# CH32V407 register map
Vendor: WCH Ltd.; File version: 1.0
Registers are 32-bit, read-write, reset 0x0 unless marked. A register's access mark holds for its fields unless they carry their own. Offsets are from the block's base; [hi:lo] are bit positions; {n}, {i} and the like mark numbered series.

## AFIO — Alternate function I/O
Base 0x40010000
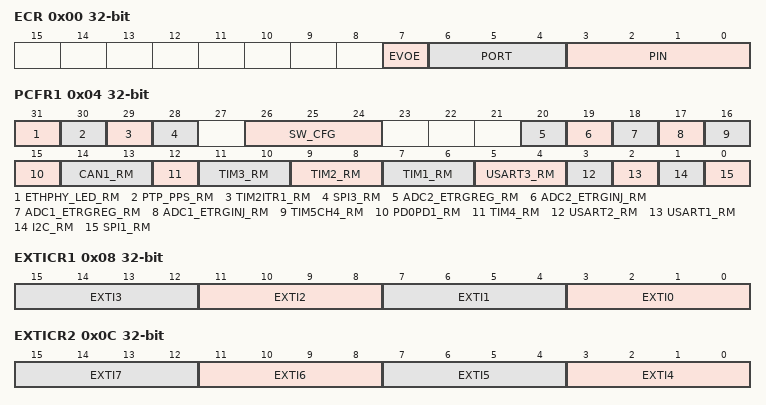
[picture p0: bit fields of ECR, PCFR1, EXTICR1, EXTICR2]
0x00 ECR — Event Control Register (AFIO_ECR)
  [7] EVOE — Event Output Enable
  [6:4] PORT — Port selection
  [3:0] PIN — Pin selection
0x04 PCFR1 — AF remap and debug I/O configuration register (AFIO_PCFR1)
  [31] ETHPHY_LED_RM — ETH PHY LED remapping
  [30] PTP_PPS_RM — Ethernet PTP_PPS remapping
  [29] TIM2ITR1_RM — TIM2 internally triggers 1 remapping
  [28] SPI3_RM — SPI3 remapping
  [26:24] SW_CFG — Serial wire JTAG configuration
  [20] ADC2_ETRGREG_RM — ADC 2 external trigger regular conversion remapping
  [19] ADC2_ETRGINJ_RM — ADC 2 External trigger injected conversion remapping
  [18] ADC1_ETRGREG_RM — ADC 1 external trigger regular conversion remapping
  [17] ADC1_ETRGINJ_RM — ADC 1 External trigger injected conversion remapping
  [16] TIM5CH4_RM — TIM5 channel4 internal remap
  [15] PD0PD1_RM — Port D0/Port D1 mapping on OSCIN/OSCOUT
  [14:13] CAN1_RM — CAN1 remapping
  [12] TIM4_RM — TIM4 remapping
  [11:10] TIM3_RM — TIM3 remapping
  [9:8] TIM2_RM — TIM2 remapping
  [7:6] TIM1_RM — TIM1 remapping
  [5:4] USART3_RM — USART3 remapping
  [3] USART2_RM — USART2 remapping
  [2] USART1_RM — USART1 remapping
  [1] I2C_RM — I2C remapping
  [0] SPI1_RM — SPI1 remapping
0x08 EXTICR1 — External interrupt configuration register 1 (AFIO_EXTICR1)
  [4n+3:4n] EXTI{n} (n=0..3) — EXTI{n} configuration
0x0C EXTICR2 — External interrupt configuration register 2 (AFIO_EXTICR2)
  [4n-13:4n-16] EXTI{n} (n=4..7) — EXTI{n} configuration
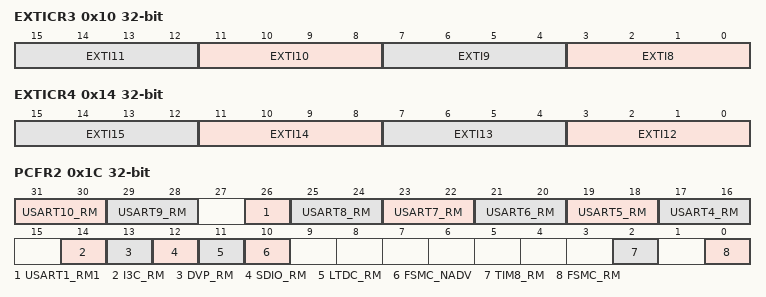
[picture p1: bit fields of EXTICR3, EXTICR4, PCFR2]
0x10 EXTICR3 — External interrupt configuration register 3 (AFIO_EXTICR3)
  [4n-29:4n-32] EXTI{n} (n=8..11) — EXTI{n} configuration
0x14 EXTICR4 — External interrupt configuration register 4 (AFIO_EXTICR4)
  [4n-45:4n-48] EXTI{n} (n=12..15) — EXTI{n} configuration
0x1C PCFR2 — AF remap and debug I/O configuration register (AFIO_PCFR2)
  [31:30] USART10_RM — USART10 remapping
  [29:28] USART9_RM — USART9 remapping
  [26] USART1_RM1 — UART1 remapping
  [2n+9:2n+8] USART{n}_RM (n=4..8) — USART{n} remapping
  [14] I3C_RM — I3C remapping
  [13] DVP_RM — DVP remapping
  [12] SDIO_RM — SDIO remapping
  [11] LTDC_RM — LTDC remapping
  [10] FSMC_NADV
  [2] TIM8_RM — TIM8 remapping
  [0] FSMC_RM — FSMC remapping

## DAC — Digital to analog converter
Base 0x40007400
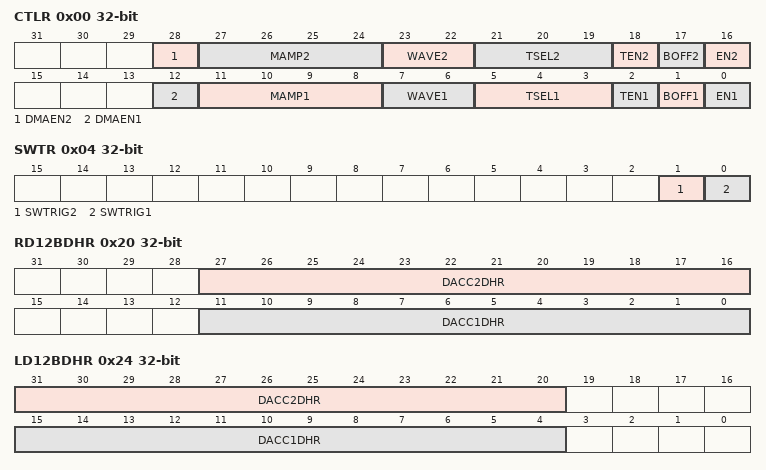
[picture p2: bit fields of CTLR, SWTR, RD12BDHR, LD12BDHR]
0x00 CTLR — Control register (DAC_CR)
  [28] DMAEN2 — DAC channel2 DMA enable
  [27:24] MAMP2 — DAC channel2 mask/amplitude selector
  [23:22] WAVE2 — DAC channel2 noise/triangle wave generation enable
  [21:19] TSEL2 — DAC channel2 trigger selection
  [18] TEN2 — DAC channel2 trigger enable
  [17] BOFF2 — DAC channel2 output buffer disable
  [16] EN2 — DAC channel2 enable
  [12] DMAEN1 — DAC channel1 DMA enable
  [11:8] MAMP1 — DAC channel1 mask/amplitude selector
  [7:6] WAVE1 — DAC channel1 noise/triangle wave generation enable
  [5:3] TSEL1 — DAC channel1 trigger selection
  [2] TEN1 — DAC channel1 trigger enable
  [1] BOFF1 — DAC channel1 output buffer disable
  [0] EN1 — DAC channel1 enable
0x04 SWTR wo — DAC software trigger register (DAC_SWTRIGR)
  [1] SWTRIG2 — DAC channel2 software trigger
  [0] SWTRIG1 — DAC channel1 software trigger
0x08 R12BDHR1 — DAC channel1 12-bit right-aligned data holding register(DAC_DHR12R1)
  [11:0] DACC1DHR — DAC channel1 12-bit right-aligned data
0x0C L12BDHR1 — DAC channel1 12-bit left aligned data holding register (DAC_DHR12L1)
  [15:4] DACC1DHR — DAC channel1 12-bit left-aligned data
0x10 R8BDHR1 — DAC channel1 8-bit right aligned data holding register (DAC_DHR8R1)
  [7:0] DACC1DHR — DAC channel1 8-bit right-aligned data
0x14 R12BDHR2 — DAC channel2 12-bit right aligned data holding register (DAC_DHR12R2)
  [11:0] DACC2DHR — DAC channel2 12-bit right-aligned data
0x18 L12BDHR2 — DAC channel2 12-bit left aligned data holding register (DAC_DHR12L2)
  [15:4] DACC2DHR — DAC channel2 12-bit left-aligned data
0x1C R8BDHR2 — DAC channel2 8-bit right-aligned data holding register (DAC_DHR8R2)
  [7:0] DACC2DHR — DAC channel2 8-bit right-aligned data
0x20 RD12BDHR — Dual DAC 12-bit right-aligned data holding register (DAC_DHR12RD), Bits 31:28 Reserved, Bits 15:12 Reserved
  [27:16] DACC2DHR — DAC channel2 12-bit right-aligned data
  [11:0] DACC1DHR — DAC channel1 12-bit right-aligned data
0x24 LD12BDHR — DUAL DAC 12-bit left aligned data holding register (DAC_DHR12LD), Bits 19:16 Reserved, Bits 3:0 Reserved
  [31:20] DACC2DHR — DAC channel2 12-bit right-aligned data
  [15:4] DACC1DHR — DAC channel1 12-bit left-aligned data
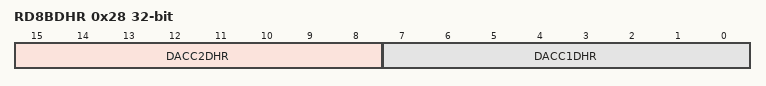
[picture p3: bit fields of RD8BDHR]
0x28 RD8BDHR — DUAL DAC 8-bit right aligned data holding register (DAC_DHR8RD), Bits 31:16 Reserved
  [15:8] DACC2DHR — DAC channel2 8-bit right-aligned data
  [7:0] DACC1DHR — DAC channel1 8-bit right-aligned data
0x2C DOR1 ro — DAC channel1 data output register (DAC_DOR1)
  [11:0] DACC1DOR — DAC channel1 data output
0x30 DOR2 ro — DAC channel2 data output register (DAC_DOR2)
  [11:0] DACC2DOR — DAC channel2 data output
